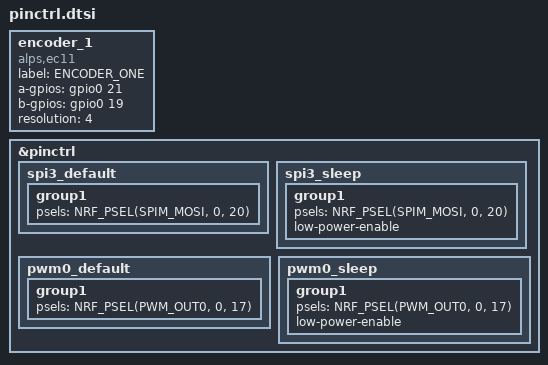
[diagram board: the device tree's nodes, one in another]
/*
 * Copyright (c) 2022 The ZMK Contributors
 * SPDX-License-Identifier: MIT
 */

	encoder_1: encoder_1 {
		compatible = "alps,ec11";
		label = "ENCODER_ONE";
		a-gpios = <&gpio0 21 (GPIO_ACTIVE_HIGH | GPIO_PULL_UP)>;
		b-gpios = <&gpio0 19 (GPIO_ACTIVE_HIGH | GPIO_PULL_UP)>;
		resolution = <4>;
		status = "okay";
    };

&pinctrl {
	spi3_default: spi3_default {
		group1 {
			psels = <NRF_PSEL(SPIM_MOSI, 0, 20)>;
		};
	};

	spi3_sleep: spi3_sleep {
		group1 {
			psels = <NRF_PSEL(SPIM_MOSI, 0, 20)>;
			low-power-enable;
		};
	};
	pwm0_default: pwm0_default {
		group1 {
			psels = <NRF_PSEL(PWM_OUT0, 0, 17)>;
		};
	};
	pwm0_sleep: pwm0_sleep {
		group1 {
			psels = <NRF_PSEL(PWM_OUT0, 0, 17)>;
			low-power-enable;
		};
	};
};
